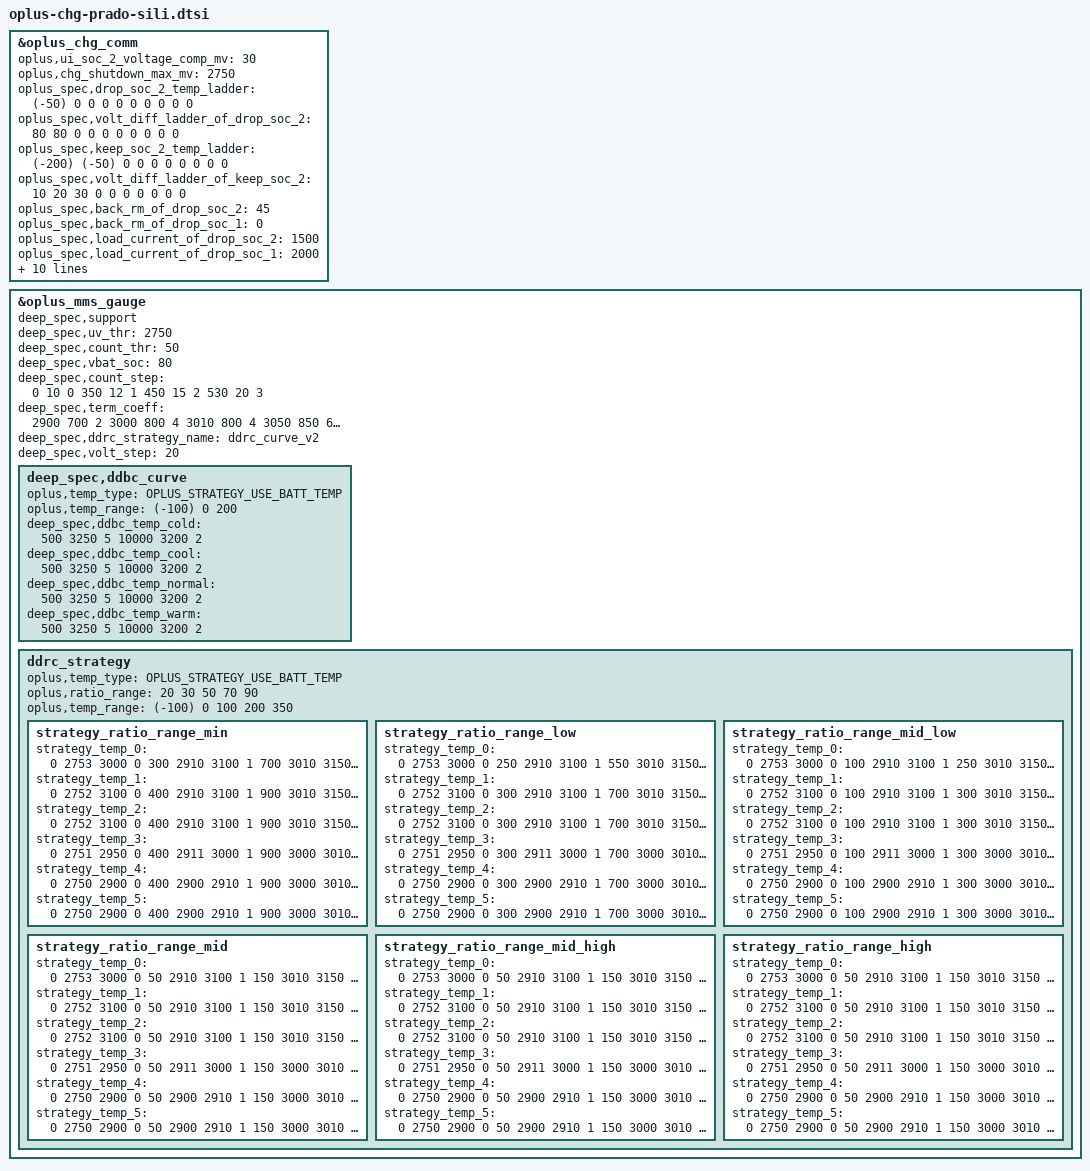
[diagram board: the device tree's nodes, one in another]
#include <dt-bindings/iio/qcom,spmi-adc5-gen3-pmxr2230.h>
#include <dt-bindings/iio/qcom,spmi-adc5-gen3-pmiv0104.h>
#include <dt-bindings/iio/qcom,spmi-adc5-gen3-pmk8550.h>
#include "oplus-chg-8650.h.dtsi"

&oplus_chg_comm {
	oplus,ui_soc_2_voltage_comp_mv = <30>;
	oplus,chg_shutdown_max_mv = <2750>;

	oplus_spec,drop_soc_2_temp_ladder = <(-50) 0 0 0 0 0 0 0 0 0>;
	oplus_spec,volt_diff_ladder_of_drop_soc_2 = <80 80 0 0 0 0 0 0 0 0>;
	oplus_spec,keep_soc_2_temp_ladder = <(-200) (-50) 0 0 0 0 0 0 0 0>;
	oplus_spec,volt_diff_ladder_of_keep_soc_2 = <10 20 30 0 0 0 0 0 0 0>;
	oplus_spec,back_rm_of_drop_soc_2 = <45>;
	oplus_spec,back_rm_of_drop_soc_1 = <0>;
	oplus_spec,load_current_of_drop_soc_2 = <1500>;
	oplus_spec,load_current_of_drop_soc_1 = <2000>;
	oplus_spec,current_limit_of_drop_soc_2 = <700>;
	oplus_spec,volt_of_fast_drop_soc_1 = <2750>;
	oplus_spec,support_uisoc_low_battery_control;
	oplus_spec,soc_down_ladder = <2 11 60 95 100 0 0 0 0 0>;
	oplus_spec,soc_down_delay_hz_ladder = <20 20 40 60 150 300 0 0 0 0>;
	oplus_spec,soc_down_chg_delay_hz_ladder = <90 40 40 60 150 300 0 0 0 0>;
	oplus_spec,soc_down_default_delay_hz = <40>;
};

&oplus_mms_gauge {
	deep_spec,support;
	deep_spec,uv_thr = <2750>;
	deep_spec,count_thr = <50>;
	deep_spec,vbat_soc = <80>;
	deep_spec,count_step = <0 10 0
				350 12 1
				450 15 2
				530 20 3>;
	deep_spec,term_coeff = <2900 700 2
				3000 800 4
				3010 800 4
				3050 850 6
				3100 950 8
				3110 950 8
				3150 1050 10
				3160 1050 10
				3200 1150 12
				3210 1150 12
				3260 1250 12>;
	deep_spec,ddrc_strategy_name = "ddrc_curve_v2";
	deep_spec,volt_step = <20>;
	deep_spec,ddbc_curve {
			oplus,temp_type = <OPLUS_STRATEGY_USE_BATT_TEMP>;
			oplus,temp_range = <(-100) 0 200>;
			deep_spec,ddbc_temp_cold = <500 3250 5
						   10000 3200 2>;
			deep_spec,ddbc_temp_cool = <500 3250 5
						   10000 3200 2>;
			deep_spec,ddbc_temp_normal = <500 3250 5
						   10000 3200 2>;
			deep_spec,ddbc_temp_warm = <500 3250 5
						   10000 3200 2>;
	};
	ddrc_strategy {
		oplus,temp_type = <OPLUS_STRATEGY_USE_BATT_TEMP>;
		oplus,ratio_range = <20 30 50 70 90>;
		oplus,temp_range = <(-100) 0 100 200 350>;
		strategy_ratio_range_min {
				strategy_temp_0 = <0 2753 3000 0
						300 2910 3100 1
						700 3010 3150 2
						1100 3061 3160 3
						1500 3111 3210 4
						1900 3161 3260 5>;
				strategy_temp_1 = <0 2752 3100 0
						400 2910 3100 1
						900 3010 3150 2
						1400 3061 3160 3
						1900 3111 3210 4
						2400 3161 3260 5>;
				strategy_temp_2 = <0 2752 3100 0
						400 2910 3100 1
						900 3010 3150 2
						1400 3061 3160 3
						1900 3111 3210 4
						2400 3161 3260 5>;
				strategy_temp_3 = <0 2751 2950 0
						400 2911 3000 1
						900 3000 3010 2
						1400 3060 3110 3
						1900 3110 3160 4
						2400 3160 3210 5>;
				strategy_temp_4 = <0 2750 2900 0
						400 2900 2910 1
						900 3000 3010 2
						1400 3050 3050 3
						1900 3100 3100 4
						2400 3150 3150 5>;
				strategy_temp_5 = <0 2750 2900 0
						400 2900 2910 1
						900 3000 3010 2
						1400 3050 3050 3
						1900 3100 3100 4
						2400 3150 3150 5>;
			};
			strategy_ratio_range_low {
				strategy_temp_0 = <0 2753 3000 0
						250 2910 3100 1
						550 3010 3150 2
						850 3110 3160 3
						1150 3160 3210 4
						1450 3210 3260 5>;
				strategy_temp_1 = <0 2752 3100 0
						300 2910 3100 1
						700 3010 3150 2
						1100 3061 3160 3
						1500 3111 3210 4
						1900 3161 3260 5>;
				strategy_temp_2 = <0 2752 3100 0
						300 2910 3100 1
						700 3010 3150 2
						1100 3061 3160 3
						1500 3111 3210 4
						1900 3161 3260 5>;
				strategy_temp_3 = <0 2751 2950 0
						300 2911 3000 1
						700 3000 3010 2
						1100 3060 3110 3
						1500 3110 3160 4
						1900 3160 3210 5>;
				strategy_temp_4 = <0 2750 2900 0
						300 2900 2910 1
						700 3000 3010 2
						1100 3050 3050 3
						1500 3100 3100 4
						1900 3150 3150 5>;
				strategy_temp_5 = <0 2750 2900 0
						300 2900 2910 1
						700 3000 3010 2
						1100 3050 3050 3
						1500 3100 3100 4
						1900 3150 3150 5>;
			};
			strategy_ratio_range_mid_low {
				strategy_temp_0 = <0 2753 3000 0
						100 2910 3100 1
						250 3010 3150 2
						400 3110 3160 3
						550 3160 3210 4
						700 3210 3260 5>;
				strategy_temp_1 = <0 2752 3100 0
						100 2910 3100 1
						300 3010 3150 2
						600 3061 3160 3
						900 3111 3210 4
						1200 3161 3260 5>;
				strategy_temp_2 = <0 2752 3100 0
						100 2910 3100 1
						300 3010 3150 2
						600 3061 3160 3
						900 3111 3210 4
						1200 3161 3260 5>;
				strategy_temp_3 = <0 2751 2950 0
						100 2911 3000 1
						300 3000 3010 2
						600 3060 3110 3
						900 3110 3160 4
						1200 3160 3210 5>;
				strategy_temp_4 = <0 2750 2900 0
						100 2900 2910 1
						300 3000 3010 2
						600 3050 3050 3
						900 3100 3100 4
						1200 3150 3150 5>;
				strategy_temp_5 = <0 2750 2900 0
						100 2900 2910 1
						300 3000 3010 2
						600 3050 3050 3
						900 3100 3100 4
						1200 3150 3150 5>;
			};
			strategy_ratio_range_mid {
				strategy_temp_0 = <0 2753 3000 0
						50 2910 3100 1
						150 3010 3150 2
						300 3110 3160 3
						450 3160 3210 4
						600 3210 3260 5>;
				strategy_temp_1 = <0 2752 3100 0
						50 2910 3100 1
						150 3010 3150 2
						350 3061 3160 3
						550 3111 3210 4
						750 3161 3260 5>;
				strategy_temp_2 = <0 2752 3100 0
						50 2910 3100 1
						150 3010 3150 2
						350 3061 3160 3
						550 3111 3210 4
						750 3161 3260 5>;
				strategy_temp_3 = <0 2751 2950 0
						50 2911 3000 1
						150 3000 3010 2
						350 3060 3110 3
						550 3110 3160 4
						750 3160 3210 5>;
				strategy_temp_4 = <0 2750 2900 0
						50 2900 2910 1
						150 3000 3010 2
						350 3050 3050 3
						550 3100 3100 4
						750 3150 3150 5>;
				strategy_temp_5 = <0 2750 2900 0
						50 2900 2910 1
						150 3000 3010 2
						350 3050 3050 3
						550 3100 3100 4
						750 3150 3150 5>;
			};
			strategy_ratio_range_mid_high {
				strategy_temp_0 = <0 2753 3000 0
						50 2910 3100 1
						150 3010 3150 2
						250 3110 3160 3
						350 3160 3210 4
						450 3210 3260 5>;
				strategy_temp_1 = <0 2752 3100 0
						50 2910 3100 1
						150 3010 3150 2
						250 3061 3160 3
						350 3111 3210 4
						450 3161 3260 5>;
				strategy_temp_2 = <0 2752 3100 0
						50 2910 3100 1
						150 3010 3150 2
						250 3061 3160 3
						350 3111 3210 4
						450 3161 3260 5>;
				strategy_temp_3 = <0 2751 2950 0
						50 2911 3000 1
						150 3000 3010 2
						250 3060 3110 3
						350 3110 3160 4
						450 3160 3210 5>;
				strategy_temp_4 = <0 2750 2900 0
						50 2900 2910 1
						150 3000 3010 2
						250 3100 3100 3
						350 3150 3150 4
						450 3200 3200 5>;
				strategy_temp_5 = <0 2750 2900 0
						50 2900 2910 1
						150 3000 3010 2
						250 3100 3100 3
						350 3150 3150 4
						450 3200 3200 5>;
			};
			strategy_ratio_range_high {
				strategy_temp_0 = <0 2753 3000 0
						50 2910 3100 1
						150 3010 3150 2
						250 3110 3160 3
						350 3160 3210 4
						450 3210 3260 5>;
				strategy_temp_1 = <0 2752 3100 0
						50 2910 3100 1
						150 3010 3150 2
						250 3061 3160 3
						350 3111 3210 4
						450 3161 3260 5>;
				strategy_temp_2 = <0 2752 3100 0
						50 2910 3100 1
						150 3010 3150 2
						250 3061 3160 3
						350 3111 3210 4
						450 3161 3260 5>;
				strategy_temp_3 = <0 2751 2950 0
						50 2911 3000 1
						150 3000 3010 2
						250 3060 3110 3
						350 3110 3160 4
						450 3160 3210 5>;
				strategy_temp_4 = <0 2750 2900 0
						50 2900 2910 1
						150 3000 3010 2
						250 3100 3100 3
						350 3150 3150 4
						450 3200 3200 5>;
				strategy_temp_5 = <0 2750 2900 0
						50 2900 2910 1
						150 3000 3010 2
						250 3100 3100 3
						350 3150 3150 4
						450 3200 3200 5>;
			};
	};
};

